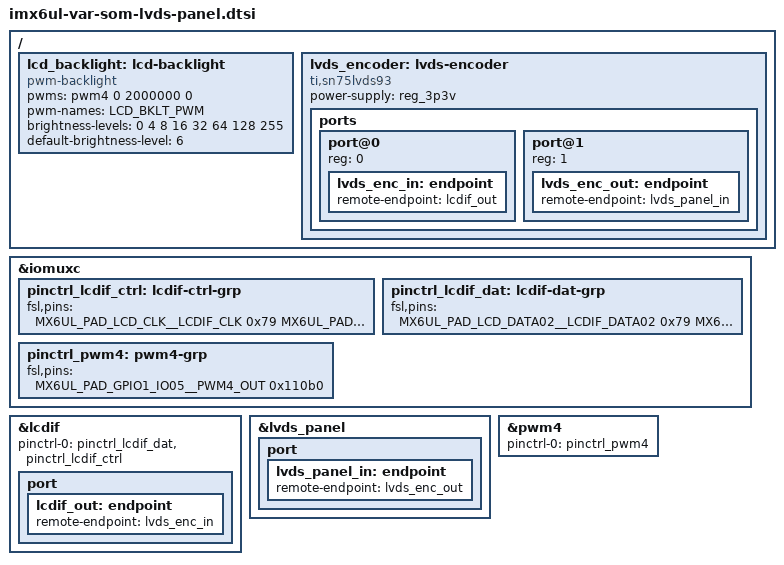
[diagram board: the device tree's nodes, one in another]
// SPDX-License-Identifier: GPL-2.0+
/*
 * LVDS panel support for Variscite VAR-SOM-6UL module.
 *
 * Copyright 2019-2024 Variscite Ltd.
 * Copyright 2026 Dimonoff
 */

/ {
	lcd_backlight: lcd-backlight {
		compatible = "pwm-backlight";
		pwms = <&pwm4 0 2000000 0>;
		pwm-names = "LCD_BKLT_PWM";
		brightness-levels = <0 4 8 16 32 64 128 255>;
		default-brightness-level = <6>;
		status = "okay";
	};

	lvds_encoder: lvds-encoder {
		compatible = "ti,sn75lvds93", "lvds-encoder";
		power-supply = <&reg_3p3v>;

		ports {
			#address-cells = <1>;
			#size-cells = <0>;

			port@0 {
				reg = <0>;

				lvds_enc_in: endpoint {
					remote-endpoint = <&lcdif_out>;
				};
			};

			port@1 {
				reg = <1>;

				lvds_enc_out: endpoint {
					remote-endpoint = <&lvds_panel_in>;
				};
			};
		};
	};
};

&iomuxc {
	pinctrl_lcdif_ctrl: lcdif-ctrl-grp {
		fsl,pins = <
			MX6UL_PAD_LCD_CLK__LCDIF_CLK		0x79
			MX6UL_PAD_LCD_ENABLE__LCDIF_ENABLE	0x79
		>;
	};

	pinctrl_lcdif_dat: lcdif-dat-grp {
		fsl,pins = <
			MX6UL_PAD_LCD_DATA02__LCDIF_DATA02	0x79
			MX6UL_PAD_LCD_DATA03__LCDIF_DATA03	0x79
			MX6UL_PAD_LCD_DATA04__LCDIF_DATA04	0x79
			MX6UL_PAD_LCD_DATA05__LCDIF_DATA05	0x79
			MX6UL_PAD_LCD_DATA06__LCDIF_DATA06	0x79
			MX6UL_PAD_LCD_DATA07__LCDIF_DATA07	0x79
			MX6UL_PAD_LCD_DATA10__LCDIF_DATA10	0x79
			MX6UL_PAD_LCD_DATA11__LCDIF_DATA11	0x79
			MX6UL_PAD_LCD_DATA12__LCDIF_DATA12	0x79
			MX6UL_PAD_LCD_DATA13__LCDIF_DATA13	0x79
			MX6UL_PAD_LCD_DATA14__LCDIF_DATA14	0x79
			MX6UL_PAD_LCD_DATA15__LCDIF_DATA15	0x79
			MX6UL_PAD_LCD_DATA18__LCDIF_DATA18	0x79
			MX6UL_PAD_LCD_DATA19__LCDIF_DATA19	0x79
			MX6UL_PAD_LCD_DATA20__LCDIF_DATA20	0x79
			MX6UL_PAD_LCD_DATA21__LCDIF_DATA21	0x79
			MX6UL_PAD_LCD_DATA22__LCDIF_DATA22	0x79
			MX6UL_PAD_LCD_DATA23__LCDIF_DATA23	0x79
		>;
	};

	pinctrl_pwm4: pwm4-grp {
		fsl,pins = <
			MX6UL_PAD_GPIO1_IO05__PWM4_OUT		0x110b0 /* LCD BACKLIGHT */
		>;
	};
};

&lcdif {
	pinctrl-names = "default";
	pinctrl-0 = <&pinctrl_lcdif_dat
		     &pinctrl_lcdif_ctrl>;
	status = "okay";

	port {
		lcdif_out: endpoint {
			remote-endpoint = <&lvds_enc_in>;
		};
	};
};

&lvds_panel {
	status = "okay";

	port {
		lvds_panel_in: endpoint {
			remote-endpoint = <&lvds_enc_out>;
		};
	};
};

/* PWM LCD */
&pwm4 {
	pinctrl-names = "default";
	pinctrl-0 = <&pinctrl_pwm4>;
	status = "okay";
};
